# SF32LB58x register map
File version: 1.0
CPU: CM33 r0p1, little endian, MPU, FPU, 3 interrupt priority bits
Registers are 32-bit, read-write, reset 0x0 unless marked. A register's access mark holds for its fields unless they carry their own. Offsets are from the block's base; [hi:lo] are bit positions; 'fields as' and 'values as' point back to an identical list.

## DSI_PHY
Base 0x4001F000
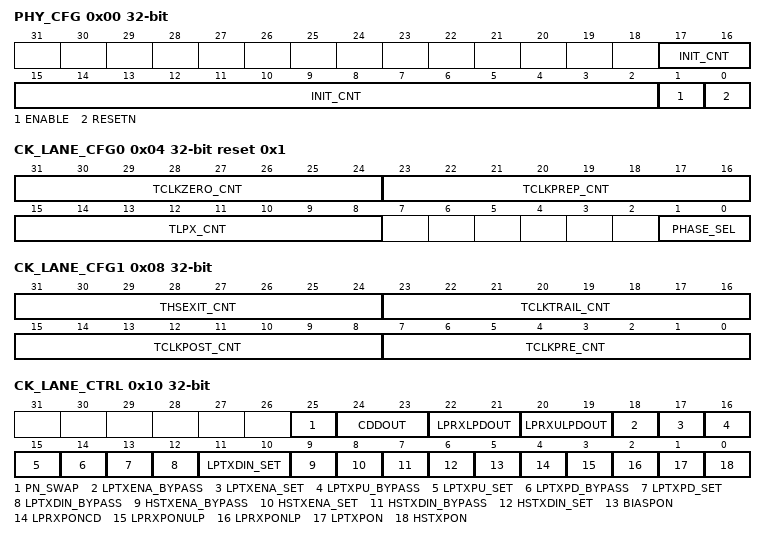
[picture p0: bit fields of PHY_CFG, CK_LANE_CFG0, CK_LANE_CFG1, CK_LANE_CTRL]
0x00 PHY_CFG
  [17:2] INIT_CNT — lane initialization counter, based on TxByteClkHS
  [1] ENABLE
  [0] RESETN
0x04 CK_LANE_CFG0 reset 0x1
  [31:24] TCLKZERO_CNT — tclkzero counter value, based on dsi_phy_clk
  [23:16] TCLKPREP_CNT — tclkprep counter value, based on dsi_phy_clk
  [15:8] TLPX_CNT — tlpx counter value, based on dsi_phy_clk
  [1:0] PHASE_SEL — clock lane output phase sel
0x08 CK_LANE_CFG1
  [31:24] THSEXIT_CNT — thsexit counter value, based on dsi_phy_clk
  [23:16] TCLKTRAIL_CNT — tclktrail counter value, based on dsi_phy_clk
  [15:8] TCLKPOST_CNT — tclkpost counter value, based on dsi_phy_clk
  [7:0] TCLKPRE_CNT — tclkpre counter value, based on dsi_phy_clk
0x0C CK_LANE_CFG2
  [7:0] TWAKEUP_CNT — twakeup counter value, based on dsi_phy_clk(Usually twakeup requires 1ms, which is over this counter range. Use TxClkExit to enter twakeup state instead of this counter.)
0x10 CK_LANE_CTRL
  [25] PN_SWAP — swap dp and dn value
  [24:23] CDDOUT — contention detect data out
  [22:21] LPRXLPDOUT — lprx lp mode data out
  [20:19] LPRXULPDOUT — lprx ulp mode data out
  [18] LPTXENA_BYPASS — bypass lptxena control from hardware logic
  [17] LPTXENA_SET — lptxena bypass value
  [16] LPTXPU_BYPASS — bypass lptx pull up control from hardware logic
  [15] LPTXPU_SET — lptxpu bypass value
  [14] LPTXPD_BYPASS — bypass lptx pull down control from hardware logic
  [13] LPTXPD_SET — lptxpd bypass value
  [12] LPTXDIN_BYPASS — bypass lptxdin control from hardware logic
  [11:10] LPTXDIN_SET — lptxdin bypass value
  [9] HSTXENA_BYPASS — bypass hstxena control from hardware logic
  [8] HSTXENA_SET — hstxena bypass value
  [7] HSTXDIN_BYPASS — bypass hstxdin control from hardware logic
  [6] HSTXDIN_SET — hstxdin bypass value
  [5] BIASPON — BIAS power on
  [4] LPRXPONCD — LP RX module CD power on
  [3] LPRXPONULP — LP RX module ULP power on
  [2] LPRXPONLP — LP RX module LP power on
  [1] LPTXPON — LP TX module power on
  [0] HSTXPON — HS TX module power on
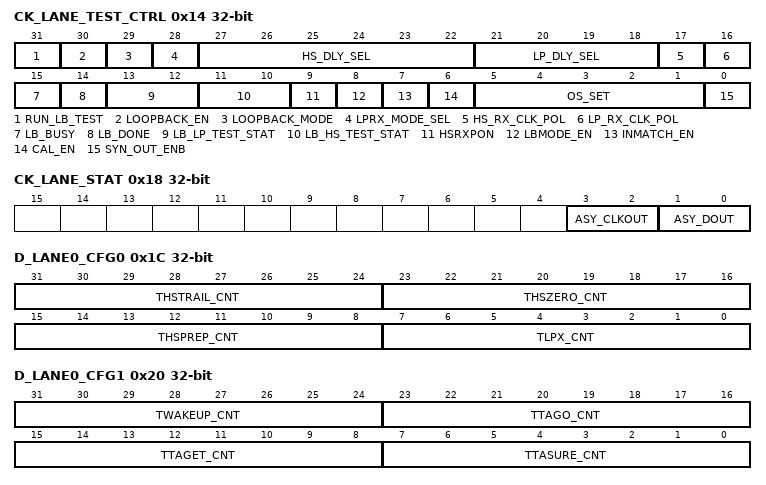
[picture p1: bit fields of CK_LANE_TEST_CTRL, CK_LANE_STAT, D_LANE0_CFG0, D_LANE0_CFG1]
0x14 CK_LANE_TEST_CTRL
  [31] RUN_LB_TEST — run loopback test
  [30] LOOPBACK_EN — ck lane loopback enable, use loopback engine to control ck lane
  [29] LOOPBACK_MODE — loopback test mode 1: lp mode 0: hs mode
  [28] LPRX_MODE_SEL — 1: lprxulp mode 0: lprxlp mode
  [27:22] HS_DLY_SEL — hs loopback data delay select
  [21:18] LP_DLY_SEL — lp loopback data delay select
  [17] HS_RX_CLK_POL — hs rx loopback latch clock polarity 1: inveter 0: normal
  [16] LP_RX_CLK_POL — lp rx loopback latch clock polarity 1: inveter 0: normal
  [15] LB_BUSY — loopback busy status
  [14] LB_DONE — loopback done status
  [13:12] LB_LP_TEST_STAT — loopback lp test status 2'b00: reserved 2'b01: sync error 2'b10: data compare error 2'b11: test pass
  [11:10] LB_HS_TEST_STAT — loopback hs test status 2'b00: reserved 2'b01: sync error 2'b10: data compare error 2'b11: test pass
  [9] HSRXPON — HS RX module power on
  [8] LBMODE_EN — loopback mode enable
  [7] INMATCH_EN — clock lane hsrx input 50ohm match enable
  [6] CAL_EN — hsrx calibration enable
  [5:1] OS_SET — hsrx offset set
  [0] SYN_OUT_ENB — synchronized output enable, low active. When disabled, asy_clkout is active.
0x18 CK_LANE_STAT
  [3:2] ASY_CLKOUT — asynchronized clock output
  [1:0] ASY_DOUT — asynchronized data output
0x1C D_LANE0_CFG0
  [31:24] THSTRAIL_CNT — thstrail counter value, based on TxByteClkHS
  [23:16] THSZERO_CNT — thszero counter value, based on TxByteClkHS
  [15:8] THSPREP_CNT — thsprep counter value, based on TxByteClkHS
  [7:0] TLPX_CNT — tlpx counter value, based on TxByteClkHS
0x20 D_LANE0_CFG1
  [31:24] TWAKEUP_CNT — twakeup counter value, based on TxClkEsc
  [23:16] TTAGO_CNT — ttago counter value, based on TxClkEsc
  [15:8] TTAGET_CNT — ttaget counter value, based on TxClkEsc
  [7:0] TTASURE_CNT — ttasure counter value, based on TxClkEsc
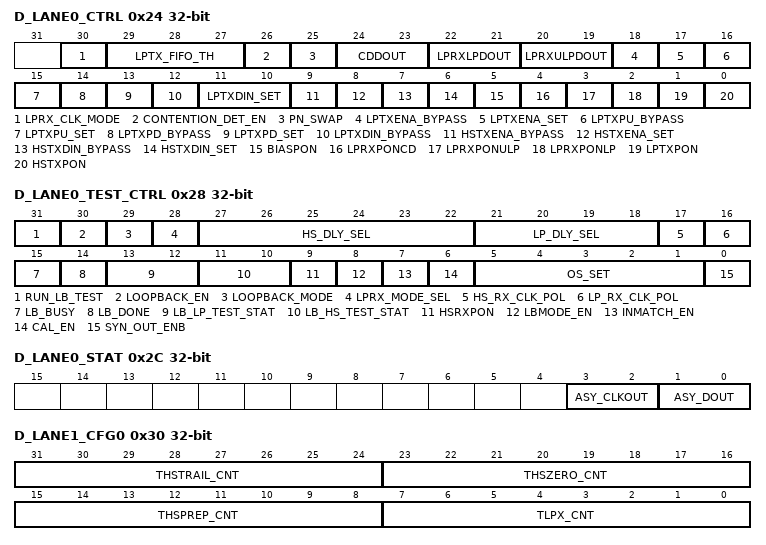
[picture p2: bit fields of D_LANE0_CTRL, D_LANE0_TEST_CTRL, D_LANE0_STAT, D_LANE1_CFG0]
0x24 D_LANE0_CTRL
  [30] LPRX_CLK_MODE — 0: use or logic to generate lprx clock 1: use xor logic to generate lprx clock
  [29:27] LPTX_FIFO_TH — LPTX mode FIFO threshold. The txready is held low if the data in FIFO exceeds the threshold.
  [26] CONTENTION_DET_EN — contention detect enable
  [25] PN_SWAP — swap dp and dn value
  [24:23] CDDOUT — contention detect data out
  [22:21] LPRXLPDOUT — lprx lp mode data out
  [20:19] LPRXULPDOUT — lprx ulp mode data out
  [18] LPTXENA_BYPASS — bypass lptxena control from hardware logic
  [17] LPTXENA_SET — lptxena bypass value
  [16] LPTXPU_BYPASS — bypass lptx pull up control from hardware logic
  [15] LPTXPU_SET — lptxpu bypass value
  [14] LPTXPD_BYPASS — bypass lptx pull down control from hardware logic
  [13] LPTXPD_SET — lptxpd bypass value
  [12] LPTXDIN_BYPASS — bypass lptxdin control from hardware logic
  [11:10] LPTXDIN_SET — lptxdin bypass value
  [9] HSTXENA_BYPASS — bypass hstxena control from hardware logic
  [8] HSTXENA_SET — hstxena bypass value
  [7] HSTXDIN_BYPASS — bypass hstxdin control from hardware logic
  [6] HSTXDIN_SET — hstxdin bypass value
  [5] BIASPON — BIAS power on
  [4] LPRXPONCD — LP RX module CD power on
  [3] LPRXPONULP — LP RX module ULP power on
  [2] LPRXPONLP — LP RX module LP power on
  [1] LPTXPON — LP TX module power on
  [0] HSTXPON — HS TX module power on
0x28 D_LANE0_TEST_CTRL
  [31] RUN_LB_TEST — run loopback test
  [30] LOOPBACK_EN — data lane0 loopback enable, use loopback engine to control data lane0
  [29] LOOPBACK_MODE — loopback test mode 1: lp mode 0: hs mode
  [28] LPRX_MODE_SEL — 1: lprxulp mode 0: lprxlp mode
  [27:22] HS_DLY_SEL — hs loopback data delay select
  [21:18] LP_DLY_SEL — lp loopback data delay select
  [17] HS_RX_CLK_POL — hs rx loopback latch clock polarity 1: inveter 0: normal
  [16] LP_RX_CLK_POL — lp rx loopback latch clock polarity 1: inveter 0: normal
  [15] LB_BUSY — loopback busy status
  [14] LB_DONE — loopback done status
  [13:12] LB_LP_TEST_STAT — loopback lp test status 2'b00: reserved 2'b01: sync error 2'b10: data compare error 2'b11: test pass
  [11:10] LB_HS_TEST_STAT — loopback hs test status 2'b00: reserved 2'b01: sync error 2'b10: data compare error 2'b11: test pass
  [9] HSRXPON — HS RX module power on
  [8] LBMODE_EN — loopback mode enable
  [7] INMATCH_EN — clock lane hsrx input 50ohm match enable
  [6] CAL_EN — hsrx calibration enable
  [5:1] OS_SET — hsrx offset set
  [0] SYN_OUT_ENB — synchronized output enable, low active. When disabled, asy_clkout is active.
0x2C D_LANE0_STAT
  fields as CK_LANE_STAT
0x30 D_LANE1_CFG0
  [31:24] THSTRAIL_CNT — thstrail counter value, based on TxByteClkHS
  [23:16] THSZERO_CNT — thszero counter value, based on TxByteClkHS
  [15:8] THSPREP_CNT — thsprep counter value, based on TxByteClkHS
  [7:0] TLPX_CNT — twakeup counter value, based on TxByteClkHS
0x34 D_LANE1_CFG1
  [7:0] TWAKEUP_CNT — twakeup counter value, based on TxClkEsc
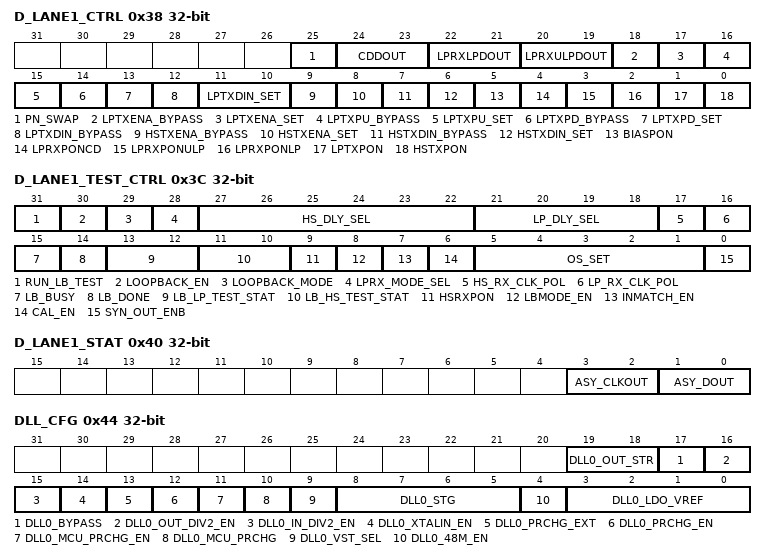
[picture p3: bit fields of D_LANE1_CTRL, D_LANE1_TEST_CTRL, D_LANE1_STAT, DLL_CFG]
0x38 D_LANE1_CTRL
  fields as CK_LANE_CTRL
0x3C D_LANE1_TEST_CTRL
  [31] RUN_LB_TEST — run loopback test
  [30] LOOPBACK_EN — data lane1 loopback enable, use loopback engine to control data lane1
  [29] LOOPBACK_MODE — loopback test mode 1: lp mode 0: hs mode
  [28] LPRX_MODE_SEL — 1: lprxulp mode 0: lprxlp mode
  [27:22] HS_DLY_SEL — hs loopback data delay select
  [21:18] LP_DLY_SEL — lp loopback data delay select
  [17] HS_RX_CLK_POL — hs rx loopback latch clock polarity 1: inveter 0: normal
  [16] LP_RX_CLK_POL — lp rx loopback latch clock polarity 1: inveter 0: normal
  [15] LB_BUSY — loopback busy status
  [14] LB_DONE — loopback done status
  [13:12] LB_LP_TEST_STAT — loopback lp test status 2'b00: reserved 2'b01: sync error 2'b10: data compare error 2'b11: test pass
  [11:10] LB_HS_TEST_STAT — loopback hs test status 2'b00: reserved 2'b01: sync error 2'b10: data compare error 2'b11: test pass
  [9] HSRXPON — HS RX module power on
  [8] LBMODE_EN — loopback mode enable
  [7] INMATCH_EN — clock lane hsrx input 50ohm match enable
  [6] CAL_EN — hsrx calibration enable
  [5:1] OS_SET — hsrx offset set
  [0] SYN_OUT_ENB — synchronized output enable, low active. When disabled, asy_clkout is active.
0x40 D_LANE1_STAT
  fields as CK_LANE_STAT
0x44 DLL_CFG
  [19:18] DLL0_OUT_STR — dll0 output strength control
  [17] DLL0_BYPASS — bypass dll0 core, output input clock
  [16] DLL0_OUT_DIV2_EN — enable output div2 1: output clock is divided by 2 0: output clock is not divided by 2
  [15] DLL0_IN_DIV2_EN — enable input div2 1: input reference clock is divided by 2 0: input reference clock is not divided by 2
  [14] DLL0_XTALIN_EN — select xtal48M clock as input clock 1: use xtal 48M 0: use rc 48M
  [13] DLL0_PRCHG_EXT — external precharge DLL0 vctrl
  [12] DLL0_PRCHG_EN — enable precharge DLL0 vctrl to avoid false lock
  [11] DLL0_MCU_PRCHG_EN — enable MCU/FIRMWARE control DLL0 precharge
  [10] DLL0_MCU_PRCHG — MCU/FIRMWARE control DLL0 precharge
  [9] DLL0_VST_SEL — pre-charge time select
  [8:5] DLL0_STG — DLL0 output clock frequency select
  [4] DLL0_48M_EN — enable 48MHz input DLL0 delay chain. Enable the delay chain when the clock to dll core is 48M.(consider input clock clock divider)
  [3:0] DLL0_LDO_VREF — DLL0 LDO output select
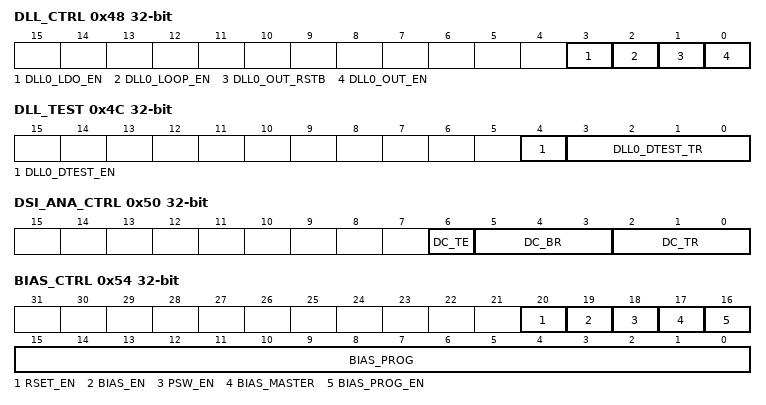
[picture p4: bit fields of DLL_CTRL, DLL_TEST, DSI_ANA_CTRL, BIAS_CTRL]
0x48 DLL_CTRL
  [3] DLL0_LDO_EN — DLL0 LDO enable
  [2] DLL0_LOOP_EN — enable DLL0 loop, reset delay chain to min delay by rising triggle
  [1] DLL0_OUT_RSTB — reset DLL0 output to 0
  [0] DLL0_OUT_EN — DLL0 output gate enable
0x4C DLL_TEST
  [4] DLL0_DTEST_EN — DLL0 dtest enable
  [3:0] DLL0_DTEST_TR — DLL0 dtest select
0x50 DSI_ANA_CTRL
  [6] DC_TE — Master switch to enable DC test
  [5:3] DC_BR — DC tst Block select
  [2:0] DC_TR — DC testpoint select
0x54 BIAS_CTRL
  [20] RSET_EN — set Res enable
  [19] BIAS_EN — BIAS enable
  [18] PSW_EN — Power switch for AVDD18 enable
  [17] BIAS_MASTER — not used
  [16] BIAS_PROG_EN — BIAS program enable
  [15:0] BIAS_PROG — [15] reserved [14:11] 1.2v control [10] HSRX 1.5G enable [9:7] 0.4v control [6] LPRX half bias enable [5:3] LPTX bias control [2:0] lane bias control
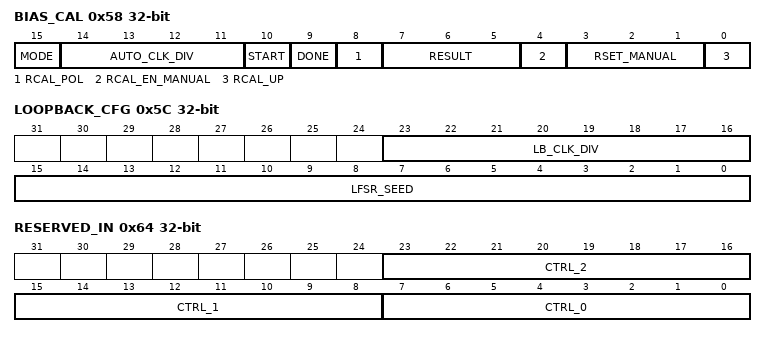
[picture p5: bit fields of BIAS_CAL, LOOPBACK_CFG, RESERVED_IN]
0x58 BIAS_CAL
  [15] MODE — calibration mode 1'b0: auto mode 1'b1: manual mode
  [14:11] AUTO_CLK_DIV — auto mode calibration clock divider divider ratio is 2^AUTO_CLK_DIV
  [10] START — start automatic calibration
  [9] DONE — auto calibration done indicator
  [8] RCAL_POL — auto calibration rcal_up polarity
  [7:5] RESULT — auto calibration res result
  [4] RCAL_EN_MANUAL — manual mode RCAL enable
  [3:1] RSET_MANUAL — manual mode RSET control
  [0] RCAL_UP — RCAL flag output, 1 require RSET increase
0x5C LOOPBACK_CFG
  [23:16] LB_CLK_DIV — loopback lpmode clock divider
  [15:0] LFSR_SEED — loopback lfsr seed
0x60 MISC_CFG
  [7:0] TPULLUP_CNT — data lane lptxpu delay time
0x64 RESERVED_IN
  [23:16] CTRL_2 — reserved control 2
  [15:8] CTRL_1 — reserved control 1
  [7:0] CTRL_0 — reserved control 0
0x68 RESERVED_OUT
  [7:0] STAT — reserved status
